# S6E2H1xF register map
Vendor: Cypress; File version: 2.1
CPU: CM4 r0p1, little endian, MPU, FPU, 4 interrupt priority bits
Registers are 32-bit, read-write, reset 0x0 unless marked. A register's access mark holds for its fields unless they carry their own. Offsets are from the block's base; [hi:lo] are bit positions; {n}, {i} and the like mark numbered series.

## CLK_GATING — Peripheral Clock Gating
Base 0x4003C100
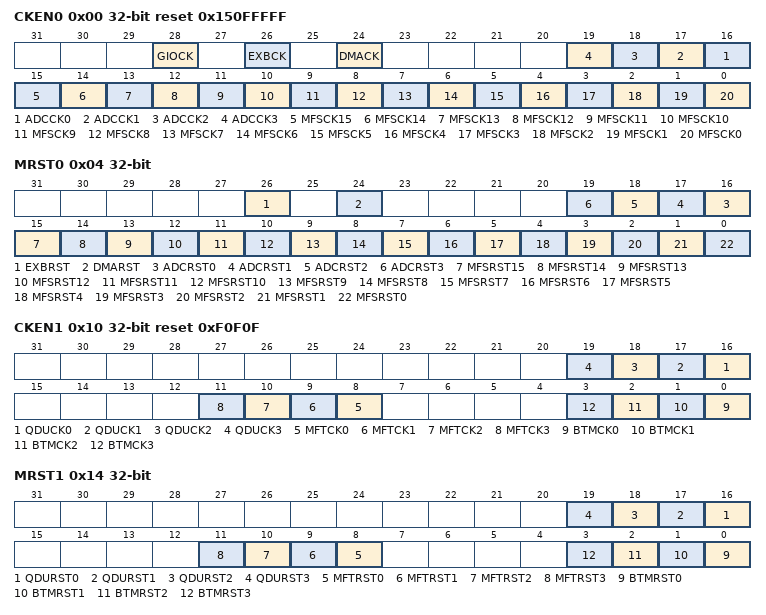
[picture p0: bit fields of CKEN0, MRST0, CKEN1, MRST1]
0x00 CKEN0 reset 0x150FFFFF — Peripheral Function Clock Control Register 0 [BHW]
  [28] GIOCK — Settings for operation clock supplying and gating to GPIO function
  [26] EXBCK — Settings for operation clock supplying and gating of external bus interface function
  [24] DMACK — Supplying and gating settings of DMAC operation clock
  [n+16] ADCCK{n} (n=0..3) — Settings for operation clock supplying and gating to A/D converter unit {n}
  [15] MFSCK15 — Settings for operation clock supply and gating to multi-function serial interface ch.15
  [14] MFSCK14 — Settings for operation clock supply and gating to multi-function serial interface ch.14
  [13] MFSCK13 — Settings for operation clock supply and gating to multi-function serial interface ch.13
  [12] MFSCK12 — Settings for operation clock supply and gating to multi-function serial interface ch.12
  [11] MFSCK11 — Settings for operation clock supply and gating to multi-function serial interface ch.11
  [10] MFSCK10 — Settings for operation clock supply and gating to multi-function serial interface ch.10
  [9] MFSCK9 — Settings for operation clock supply and gating to multi-function serial interface ch.9
  [8] MFSCK8 — Settings for operation clock supply and gating to multi-function serial interface ch.8
  [7] MFSCK7 — Settings for operation clock supply and gating to multi-function serial interface ch.7
  [6] MFSCK6 — Settings for operation clock supply and gating to multi-function serial interface ch.6
  [5] MFSCK5 — Settings for operation clock supply and gating to multi-function serial interface ch.5
  [4] MFSCK4 — Settings for operation clock supply and gating to multi-function serial interface ch.4
  [3] MFSCK3 — Settings for operation clock supply and gating to multi-function serial interface ch.3
  [2] MFSCK2 — Settings for operation clock supply and gating to multi-function serial interface ch.2
  [1] MFSCK1 — Settings for operation clock supply and gating to multi-function serial interface ch.1
  [0] MFSCK0 — Settings for operation clock supply and gating to multi-function serial interface ch.0
0x04 MRST0 — Peripheral Function Reset Control Register 0 [BHW]
  [26] EXBRST — Reset control for external bus interface
  [24] DMARST — Reset control of DMAC
  [n+16] ADCRST{n} (n=0..3) — Reset control of A/D converter unit {n}
  [15] MFSRST15 — Control of software reset of multi-function serial interface ch.15
  [14] MFSRST14 — Control of software reset of multi-function serial interface ch.14
  [13] MFSRST13 — Control of software reset of multi-function serial interface ch.13
  [12] MFSRST12 — Control of software reset of multi-function serial interface ch.12
  [11] MFSRST11 — Control of software reset of multi-function serial interface ch.11
  [10] MFSRST10 — Control of software reset of multi-function serial interface ch.10
  [9] MFSRST9 — Control of software reset of multi-function serial interface ch.9
  [8] MFSRST8 — Control of software reset of multi-function serial interface ch.8
  [7] MFSRST7 — Control of software reset of multi-function serial interface ch.7
  [6] MFSRST6 — Control of software reset of multi-function serial interface ch.6
  [5] MFSRST5 — Control of software reset of multi-function serial interface ch.5
  [4] MFSRST4 — Control of software reset of multi-function serial interface ch.4
  [3] MFSRST3 — Control of software reset of multi-function serial interface ch.3
  [2] MFSRST2 — Control of software reset of multi-function serial interface ch.2
  [1] MFSRST1 — Control of software reset of multi-function serial interface ch.1
  [0] MFSRST0 — Control of software reset of multi-function serial interface ch.0
0x10 CKEN1 reset 0xF0F0F — Peripheral Function Clock Control Register 1 [BHW]
  [n+16] QDUCK{n} (n=0..3) — Reset control of quad counter unit {n}
  [n+8] MFTCK{n} (n=0..3) — Settings for operation clock supply and gating of multi-function timer {n} and PPG {8n}/{8n+2}/{8n+4}/{8n+6}
  [n] BTMCK{n} (n=0..3) — Settings operation clock supply and gating to base timer {4n}/{4n+1}/{4n+2}/{4n+3}
0x14 MRST1 — Peripheral Function Reset Control Register 1 [BHW]
  [n+16] QDURST{n} (n=0..3) — Reset control of quad counter unit {n}
  [n+8] MFTRST{n} (n=0..3) — Control of multi-function timer {n} and PPG {8n}/{8n+2}/{8n+4}/{8n+6} reset control
  [n] BTMRST{n} (n=0..3) — Reset control of base timer {4n}/{4n+1}/{4n+2}/{4n+3}
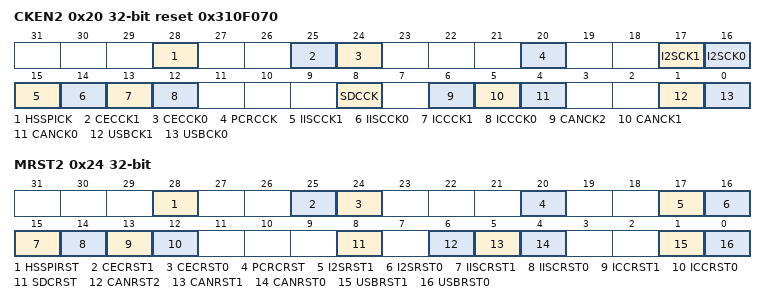
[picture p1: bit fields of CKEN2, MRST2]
0x20 CKEN2 reset 0x310F070 — Peripheral Function Clock Control Register 2 [BHW]
  [28] HSSPICK — Settings for operation clock supply and gating to Hi-Speed Quad SPI
  [25] CECCK1 — Settings for operation clock supply and gating to HDMI-CEC/Remote Control Reception ch.1
  [24] CECCK0 — Settings for operation clock supply and gating to HDMI-CEC/Remote Control Reception ch.0
  [20] PCRCCK — Settings for operation clock supply and gating to Programmable-CRC
  [17] I2SCK1 — Settings for operation clock supply and gating of I2S Interface ch.1
  [16] I2SCK0 — Settings for operation clock supply and gating of I2S Interface ch.0
  [15] IISCCK1 — Settings for operation clock supply and gating of MFS I2S Interface ch.1
  [14] IISCCK0 — Settings for operation clock supply and gating of MFS I2S Interface ch.0
  [13] ICCCK1 — Settings for operation clock supply and gating of IC Card Interface ch.1
  [12] ICCCK0 — Settings for operation clock supply and gating of IC Card Interface ch.0
  [8] SDCCK — Settings for operation clock supply and gating to SD card interface
  [6] CANCK2 — Settings for clock supply and gating to CAN controller ch.2/CAN-FD controller
  [5] CANCK1 — Settings for clock supply and gating to CAN controller ch.1
  [4] CANCK0 — Settings for clock supply and gating to CAN controller ch.0
  [1] USBCK1 — Settings for operation clock supply and gating of USB(function/host) ch.1
  [0] USBCK0 — Settings for operation clock supply and gating of USB(function/host) ch.0
0x24 MRST2 — Peripheral Function Reset Control Register 2 [BHW]
  [28] HSSPIRST — Reset control of Hi-Speed SPI controller
  [25] CECRST1 — Reset control of HDMI-CEC/Remote Control Reception ch.1
  [24] CECRST0 — Reset control of HDMI-CEC/Remote Control Reception ch.0
  [20] PCRCRST — Reset control of Programmable-CRC
  [17] I2SRST1 — Reset control of I2S Interface ch.1
  [16] I2SRST0 — Reset control of I2S Interface ch.0
  [15] IISCRST1 — Reset control of MFS I2S Interface ch.1
  [14] IISCRST0 — Reset control of MFS I2S Interface ch.0
  [13] ICCRST1 — Reset control of IC Card Interface ch.1
  [12] ICCRST0 — Reset control of IC Card Interface ch.0
  [8] SDCRST — Reset control of SD card interface
  [6] CANRST2 — Reset control of CAN controller ch.2/CAN-FD controller
  [5] CANRST1 — Reset control of CAN controller ch.1
  [4] CANRST0 — Reset control of CAN controller ch.0
  [1] USBRST1 — Reset control of USB (function/host) ch.1
  [0] USBRST0 — Reset control of USB (function/host) ch.0

## Notices in the file
Copyright (C) 2013-2016, Cypress Semiconductor Corporation or a
subsidiary of Cypress Semiconductor Corporation.  All rights reserved.
This software, including source code, documentation and related
materials ("Software"), is owned by Cypress Semiconductor Corporation or
one of its subsidiaries ("Cypress") and is protected by and subject to
worldwide patent protection (United States and foreign), United States
copyright laws and international treaty provisions. Therefore, you may use
this Software only as provided in the license agreement accompanying the
software package from which you obtained this Software ("EULA").
If no EULA applies, Cypress hereby grants you a personal, non-exclusive,
non-transferable license to copy, modify, and compile the
Software source code solely for use in connection with Cypress's
integrated circuit products.  Any reproduction, modification, translation,
compilation, or representation of this Software except as specified
above is prohibited without the express written permission of Cypress.
Disclaimer: THIS SOFTWARE IS PROVIDED AS-IS, WITH NO
WARRANTY OF ANY KIND, EXPRESS OR IMPLIED, INCLUDING,
BUT NOT LIMITED TO, NONINFRINGEMENT, IMPLIED
WARRANTIES OF MERCHANTABILITY AND FITNESS FOR A
PARTICULAR PURPOSE. Cypress reserves the right to make
changes to the Software without notice. Cypress does not assume any
liability arising out of the application or use of the Software or any
product or circuit described in the Software. Cypress does not
authorize its products for use in any products where a malfunction or
failure of the Cypress product may reasonably be expected to result in
significant property damage, injury or death ("High Risk Product"). By
including Cypress's product in a High Risk Product, the manufacturer
of such system or application assumes all risk of such use and in doing
so agrees to indemnify Cypress against all liability.
